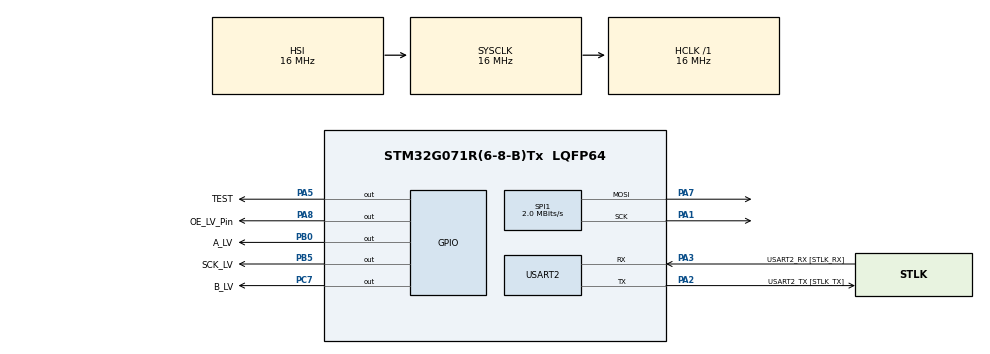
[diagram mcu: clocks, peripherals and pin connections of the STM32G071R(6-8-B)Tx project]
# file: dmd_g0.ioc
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Mcu.Family=STM32G0
Mcu.Name=STM32G071R(6-8-B)Tx
Mcu.Package=LQFP64
PA1.Mode=TX_Only_Simplex_Unidirect_Master
PA1.Signal=SPI1_SCK
PA13.GPIO_Label=TMS
PA13.Mode=Serial_Wire
PA13.Signal=SYS_SWDIO
PA14-BOOT0.GPIO_Label=TCK
PA14-BOOT0.Mode=Serial_Wire
PA14-BOOT0.Signal=SYS_SWCLK
PA2.GPIO_Label=USART2_TX [STLK_TX]
PA2.GPIO_PuPd=GPIO_PULLUP
PA2.Mode=Asynchronous
PA2.Signal=USART2_TX
PA3.GPIO_Label=USART2_RX [STLK_RX]
PA3.GPIO_PuPd=GPIO_PULLUP
PA3.Mode=Asynchronous
PA3.Signal=USART2_RX
PA5.GPIO_Label=TEST
PA5.GPIO_Speed=GPIO_SPEED_FREQ_HIGH
PA5.Signal=GPIO_Output
PA7.Mode=TX_Only_Simplex_Unidirect_Master
PA7.Signal=SPI1_MOSI
PA8.GPIO_Label=OE_LV_Pin
PA8.Signal=GPIO_Output
PB0.GPIO_Label=A_LV
PB0.Signal=GPIO_Output
PB5.GPIO_Label=SCK_LV
PB5.Signal=GPIO_Output
PC13.Mode=SYS_WakeUp1
PC13.Signal=SYS_WKUP2
PC14-OSC32_IN\ (PC14).Mode=LSE-External-Oscillator
PC14-OSC32_IN\ (PC14).Signal=RCC_OSC32_IN
PC15-OSC32_OUT\ (PC15).Mode=LSE-External-Oscillator
PC15-OSC32_OUT\ (PC15).Signal=RCC_OSC32_OUT
PC7.GPIO_Label=B_LV
PC7.Signal=GPIO_Output
PF0-OSC_IN\ (PF0).GPIO_Label=MCO
PF0-OSC_IN\ (PF0).Mode=HSE-External-Clock-Source
PF0-OSC_IN\ (PF0).Signal=RCC_OSC_IN
ProjectManager.HeapSize=0x200
ProjectManager.StackSize=0x400
ProjectManager.TargetToolchain=STM32CubeIDE
RCC.AHBFreq_Value=16000000
RCC.CortexFreq_Value=16000000
RCC.EXTERNAL_CLOCK_VALUE=12288000
RCC.HCLKFreq_Value=16000000
RCC.HSE_VALUE=8000000
RCC.HSI_VALUE=16000000
RCC.SYSCLKFreq_VALUE=16000000
RCC.VCOOutputFreq_Value=128000000
SPI1.BaudRatePrescaler=SPI_BAUDRATEPRESCALER_8
SPI1.CalculateBaudRate=2.0 MBits/s
SPI1.DataSize=SPI_DATASIZE_8BIT
SPI1.Direction=SPI_DIRECTION_2LINES
SPI1.Mode=SPI_MODE_MASTER
SPI1.VirtualType=VM_MASTER
TIM7.Prescaler=6553
USART2.VirtualMode-Asynchronous=VM_ASYNC
VP_SYS_VS_DBSignals.Mode=DisableDeadBatterySignals
VP_TIM7_VS_ClockSourceINT.Mode=Enable_Timer
board=NUCLEO-G071RB

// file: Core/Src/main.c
/* USER CODE BEGIN Header */
/**
 ******************************************************************************
 * @file           : main.c
 * @brief          : Main program body
 ******************************************************************************
 * @attention
 *
 * <h2><center>&copy; Copyright (c) 2021 STMicroelectronics.
 * All rights reserved.</center></h2>
 *
 * This software component is licensed by ST under BSD 3-Clause license,
 * the "License"; You may not use this file except in compliance with the
 * License. You may obtain a copy of the License at:
 *                        opensource.org/licenses/BSD-3-Clause
 *
 ******************************************************************************
 */
/* USER CODE END Header */
#include "main.h"
#include "spi.h"
#include "tim.h"
#include "usart.h"
#include "gpio.h"

/* USER CODE BEGIN Includes */
#include <stdio.h>
#include "../display/dmd/inc/dmd.h"
#include "../display/dmd/inc/System5x7.h"
/* USER CODE END Includes */

void SystemClock_Config(void);

int main(void) {
	/* USER CODE BEGIN 1 */
	char data[10];
	int i;
	/* USER CODE END 1 */

	/* MCU Configuration--------------------------------------------------------*/

	/* Reset of all peripherals, Initializes the Flash interface and the Systick. */
	HAL_Init();

	/* Configure the system clock */
	SystemClock_Config();

	/* Initialize all configured peripherals */
	MX_GPIO_Init();
	MX_USART2_UART_Init();
	MX_SPI1_Init();
	MX_TIM7_Init();
	/* USER CODE BEGIN 2 */
	DMD_init(1, 1);
	selectFont(System5x7);
	clearScreen(true);
	drawString(1, 1, "Init", 4, GRAPHICS_NORMAL);
	/* USER CODE END 2 */

	/* Infinite loop */
	/* USER CODE BEGIN WHILE */
	while (1) {

		sprintf(data, "%d", i++);
		clearScreen(true);
		drawString(1, 1, "Init", 1, GRAPHICS_NORMAL);
		/* USER CODE END WHILE */

	}
}

void SystemClock_Config(void) {
	RCC_OscInitTypeDef RCC_OscInitStruct = { 0 };
	RCC_ClkInitTypeDef RCC_ClkInitStruct = { 0 };
	RCC_PeriphCLKInitTypeDef PeriphClkInit = { 0 };

	/** Configure the main internal regulator output voltage
	 */
	HAL_PWREx_ControlVoltageScaling(PWR_REGULATOR_VOLTAGE_SCALE1);
	/** Initializes the RCC Oscillators according to the specified parameters
	 * in the RCC_OscInitTypeDef structure.
	 */
	RCC_OscInitStruct.OscillatorType = RCC_OSCILLATORTYPE_HSI;
	RCC_OscInitStruct.HSIState = RCC_HSI_ON;
	RCC_OscInitStruct.HSIDiv = RCC_HSI_DIV1;
	RCC_OscInitStruct.HSICalibrationValue = RCC_HSICALIBRATION_DEFAULT;
	RCC_OscInitStruct.PLL.PLLState = RCC_PLL_NONE;
	if (HAL_RCC_OscConfig(&RCC_OscInitStruct) != HAL_OK) {
		Error_Handler();
	}
	/** Initializes the CPU, AHB and APB buses clocks
	 */
	RCC_ClkInitStruct.ClockType = RCC_CLOCKTYPE_HCLK | RCC_CLOCKTYPE_SYSCLK
			| RCC_CLOCKTYPE_PCLK1;
	RCC_ClkInitStruct.SYSCLKSource = RCC_SYSCLKSOURCE_HSI;
	RCC_ClkInitStruct.AHBCLKDivider = RCC_SYSCLK_DIV1;
	RCC_ClkInitStruct.APB1CLKDivider = RCC_HCLK_DIV1;

	if (HAL_RCC_ClockConfig(&RCC_ClkInitStruct, FLASH_LATENCY_0) != HAL_OK) {
		Error_Handler();
	}
	/** Initializes the peripherals clocks
	 */
	PeriphClkInit.PeriphClockSelection = RCC_PERIPHCLK_USART2;
	PeriphClkInit.Usart2ClockSelection = RCC_USART2CLKSOURCE_PCLK1;
	if (HAL_RCCEx_PeriphCLKConfig(&PeriphClkInit) != HAL_OK) {
		Error_Handler();
	}
}

void Error_Handler(void) {
	__disable_irq();
	while (1) {
	}
}

/************************ (C) COPYRIGHT STMicroelectronics *****END OF FILE****/
